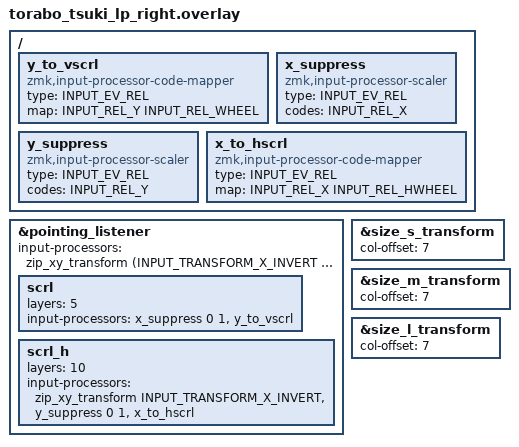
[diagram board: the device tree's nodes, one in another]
#include "torabo_tsuki_lp.dtsi"
#include <input/processors.dtsi>
#include <dt-bindings/zmk/input_transform.h>

/ {
    y_to_vscrl: y_to_vscrl {
        compatible = "zmk,input-processor-code-mapper";
        #input-processor-cells = <0>;
        type = <INPUT_EV_REL>;
        map = <INPUT_REL_Y INPUT_REL_WHEEL>;
    };

    x_suppress: x_suppress {
        compatible = "zmk,input-processor-scaler";
        #input-processor-cells = <2>;
        type = <INPUT_EV_REL>;
        codes = <INPUT_REL_X>;
    };

    y_suppress: y_suppress {
        compatible = "zmk,input-processor-scaler";
        #input-processor-cells = <2>;
        type = <INPUT_EV_REL>;
        codes = <INPUT_REL_Y>;
    };

    x_to_hscrl: x_to_hscrl {
        compatible = "zmk,input-processor-code-mapper";
        #input-processor-cells = <0>;
        type = <INPUT_EV_REL>;
        map = <INPUT_REL_X INPUT_REL_HWHEEL>;
    };

};

&pointing_listener {
    input-processors = <&zip_xy_transform (INPUT_TRANSFORM_X_INVERT | INPUT_TRANSFORM_Y_INVERT)>;

    scrl {
        layers = <5>;
        input-processors = <&x_suppress 0 1 &y_to_vscrl>;
    };

    scrl_h {
        layers = <10>;
        input-processors = <&zip_xy_transform INPUT_TRANSFORM_X_INVERT &y_suppress 0 1 &x_to_hscrl>;
    };

};

&size_s_transform {
    col-offset = <7>;
};

&size_m_transform {
    col-offset = <7>;
};

&size_l_transform {
    col-offset = <7>;
};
